AUTOSAR XML (schema 4-2-1)
package /RootP_ASWC_SATELLITE_CORE0_SWPQM
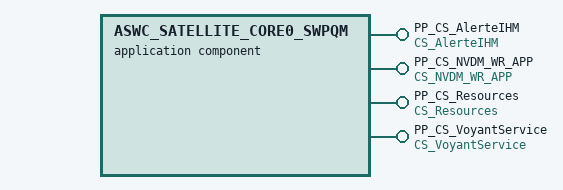
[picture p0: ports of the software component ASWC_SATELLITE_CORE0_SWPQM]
  application sw component type ASWC_SATELLITE_CORE0_SWPQM
    4 x provide port:
      PP_CS_AlerteIHM: server-com-spec{operation=Cmd, queue-length=1}, provided-interface=CS_AlerteIHM
      PP_CS_NVDM_WR_APP: server-com-spec{operation=NvDM_WrApp_Block, queue-length=1}, provided-interface=CS_NVDM_WR_APP
      PP_CS_Resources: server-com-spec{operation=Request, queue-length=1}, provided-interface=CS_Resources
      PP_CS_VoyantService: server-com-spec{operation=Piloter, queue-length=1}, provided-interface=CS_VoyantService
    behavior IB_ASWC_SATELLITE_CORE0_SWPQM: handle-termination-and-restart=NO-SUPPORT
      4 x operation invoked event:
        CS_AlerteIHM_Cmd_OIE_CORE0_SWPQM: start-on-event=RUNS_AlerteIHM_Cmd_CORE0_SWPQM, operation=PP_CS_AlerteIHM.Cmd
        CS_NVDM_WR_APP_NvDM_WrApp_Block_OIE_CORE0_SWPQM: start-on-event=RUNS_NVDM_WR_APP_NvDM_WrApp_Block_CORE0_SWPQM, operation=PP_CS_NVDM_WR_APP.NvDM_WrApp_Block
        CS_Resources_Request_OIE_CORE0_SWPQM: start-on-event=RUNS_Resources_Request_CORE0_SWPQM, operation=PP_CS_Resources.Request
        CS_VoyantService_Piloter_OIE_CORE0_SWPQM: start-on-event=RUNS_VoyantService_Piloter_CORE0_SWPQM, operation=PP_CS_VoyantService.Piloter
      4 x runnable:
        RUNS_AlerteIHM_Cmd_CORE0_SWPQM
        RUNS_NVDM_WR_APP_NvDM_WrApp_Block_CORE0_SWPQM
        RUNS_Resources_Request_CORE0_SWPQM
        RUNS_VoyantService_Piloter_CORE0_SWPQM
  swc implementation ASWC_SATELLITE_CORE0_SWPQM_Impl: programming-language=C, sw-version=1.0.0, vendor-id=0, behavior=IB_ASWC_SATELLITE_CORE0_SWPQM
    code-descriptors:
      code SRC: artifact-descriptors=autosar-engineering-object={short-label=EngObject, category=SWSRC}
    resource consumption Resources
      memory section CODE: sw-addrmethod=CODE_ASWC_SATELLITE_CORE0_SWPQM
  sw addr method CODE_ASWC_SATELLITE_CORE0_SWPQM: memory-allocation-keyword-policy=ADDR-METHOD-SHORT-NAME-AND-ALIGNMENT, section-type=CODE
